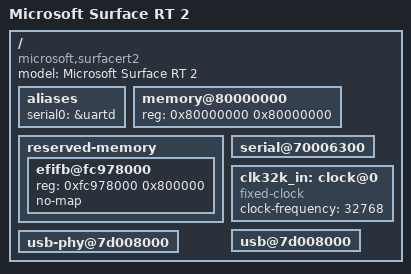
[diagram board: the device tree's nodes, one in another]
/dts-v1/;

#include <dt-bindings/input/input.h>
#include "tegra114.dtsi"

/ {
	model = "Microsoft Surface RT 2";
	compatible = "microsoft,surfacert2", "nvidia,tegra114";

	aliases {
		serial0 = &uartd;
	};

	memory@80000000 {
		reg = <0x80000000 0x80000000>;
	};

	reserved-memory {
		#address-cells = <1>;
		#size-cells = <1>;
		ranges;

		efifb@fc978000 {
			reg = <0xfc978000 0x800000>;
			no-map;
		};
	};

	serial@70006300 {
		status = "okay";
	};

	clk32k_in: clock@0 {
		compatible = "fixed-clock";
		clock-frequency = <32768>;
		#clock-cells = <0>;
	};

	usb@7d008000 {
		status = "okay";
	};

	usb-phy@7d008000 {
		status = "okay";
	};
};
